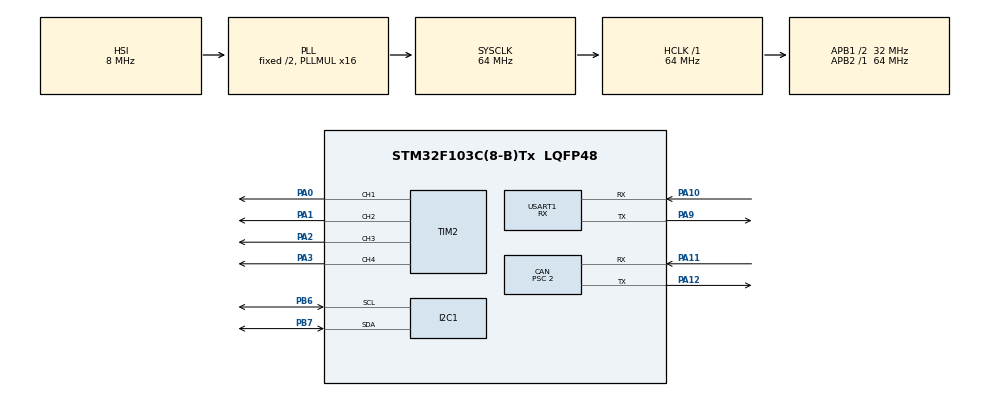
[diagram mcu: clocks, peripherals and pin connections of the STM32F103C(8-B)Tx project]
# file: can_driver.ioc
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CAN.BS1=CAN_BS1_13TQ
CAN.BS2=CAN_BS2_2TQ
CAN.CalculateTimeBit=1000
CAN.CalculateTimeQuantum=62.5
CAN.Mode=CAN_MODE_LOOPBACK
CAN.Prescaler=2
Mcu.Family=STM32F1
Mcu.Name=STM32F103C(8-B)Tx
Mcu.Package=LQFP48
NVIC.PriorityGroup=NVIC_PRIORITYGROUP_4
PA0-WKUP.Signal=S_TIM2_CH1_ETR
PA1.Signal=S_TIM2_CH2
PA10.Mode=Asynchronous
PA10.Signal=USART1_RX
PA11.Mode=Master
PA11.Signal=CAN_RX
PA12.Mode=Master
PA12.Signal=CAN_TX
PA13.Mode=Serial_Wire
PA13.Signal=SYS_JTMS-SWDIO
PA14.Mode=Serial_Wire
PA14.Signal=SYS_JTCK-SWCLK
PA2.Signal=S_TIM2_CH3
PA3.Signal=S_TIM2_CH4
PA9.Mode=Asynchronous
PA9.Signal=USART1_TX
PB6.Mode=I2C
PB6.Signal=I2C1_SCL
PB7.Mode=I2C
PB7.Signal=I2C1_SDA
ProjectManager.HeapSize=0x200
ProjectManager.StackSize=0x400
ProjectManager.TargetToolchain=STM32CubeIDE
RCC.AHBFreq_Value=64000000
RCC.APB1CLKDivider=RCC_HCLK_DIV2
RCC.APB1Freq_Value=32000000
RCC.APB1TimFreq_Value=64000000
RCC.APB2Freq_Value=64000000
RCC.APB2TimFreq_Value=64000000
RCC.HCLKFreq_Value=64000000
RCC.HSE_VALUE=16000000
RCC.PLLMUL=RCC_PLL_MUL16
RCC.SYSCLKFreq_VALUE=64000000
RCC.SYSCLKSource=RCC_SYSCLKSOURCE_PLLCLK
RCC.USBFreq_Value=64000000
SH.S_TIM2_CH1_ETR.0=TIM2_CH1,PWM Generation1 CH1
SH.S_TIM2_CH2.0=TIM2_CH2,PWM Generation2 CH2
SH.S_TIM2_CH3.0=TIM2_CH3,PWM Generation3 CH3
SH.S_TIM2_CH4.0=TIM2_CH4,PWM Generation4 CH4
TIM2.Channel-PWM\ Generation1\ CH1=TIM_CHANNEL_1
TIM2.Channel-PWM\ Generation2\ CH2=TIM_CHANNEL_2
TIM2.Channel-PWM\ Generation3\ CH3=TIM_CHANNEL_3
TIM2.Channel-PWM\ Generation4\ CH4=TIM_CHANNEL_4
USART1.Mode=MODE_RX
USART1.VirtualMode=VM_ASYNC
USART1.WordLength=WORDLENGTH_8B
VP_TIM2_VS_ClockSourceINT.Mode=Internal
board=custom

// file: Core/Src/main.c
/* USER CODE BEGIN Header */
/**
 ******************************************************************************
 * @file           : main.c
 * @brief          : Main program body
 ******************************************************************************
 * @attention
 *
 * <h2><center>&copy; Copyright (c) 2023 STMicroelectronics.
 * All rights reserved.</center></h2>
 *
 * This software component is licensed by ST under BSD 3-Clause license,
 * the "License"; You may not use this file except in compliance with the
 * License. You may obtain a copy of the License at:
 *                        opensource.org/licenses/BSD-3-Clause
 *
 ******************************************************************************
 */
/* USER CODE END Header */
#include "main.h"

CAN_HandleTypeDef hcan;

I2C_HandleTypeDef hi2c1;

TIM_HandleTypeDef htim2;

UART_HandleTypeDef huart1;

void SystemClock_Config(void);
static void MX_GPIO_Init(void);
static void MX_TIM2_Init(void);
static void MX_CAN_Init(void);
static void MX_USART1_UART_Init(void);
static void MX_I2C1_Init(void);

int main(void)
{

  /* MCU Configuration--------------------------------------------------------*/

  /* Reset of all peripherals, Initializes the Flash interface and the Systick. */
  HAL_Init();

  /* Configure the system clock */
  SystemClock_Config();

  /* Initialize all configured peripherals */
  MX_GPIO_Init();
  MX_TIM2_Init();
  MX_CAN_Init();
  MX_USART1_UART_Init();
  MX_I2C1_Init();
  /* USER CODE BEGIN 2 */

	//  Start the CAN module
//	HAL_CAN_Start(&hcan);

//	uint8_t data[8] = {'w','e','g','z','h','e','r','e'};
  /* USER CODE END 2 */

  /* Infinite loop */
	while (1)
	{

	}
}

void SystemClock_Config(void)
{
  RCC_OscInitTypeDef RCC_OscInitStruct = {0};
  RCC_ClkInitTypeDef RCC_ClkInitStruct = {0};

  /** Initializes the RCC Oscillators according to the specified parameters
  * in the RCC_OscInitTypeDef structure.
  */
  RCC_OscInitStruct.OscillatorType = RCC_OSCILLATORTYPE_HSI;
  RCC_OscInitStruct.HSIState = RCC_HSI_ON;
  RCC_OscInitStruct.HSICalibrationValue = RCC_HSICALIBRATION_DEFAULT;
  RCC_OscInitStruct.PLL.PLLState = RCC_PLL_ON;
  RCC_OscInitStruct.PLL.PLLSource = RCC_PLLSOURCE_HSI_DIV2;
  RCC_OscInitStruct.PLL.PLLMUL = RCC_PLL_MUL16;
  if (HAL_RCC_OscConfig(&RCC_OscInitStruct) != HAL_OK)
  {
    Error_Handler();
  }
  /** Initializes the CPU, AHB and APB buses clocks
  */
  RCC_ClkInitStruct.ClockType = RCC_CLOCKTYPE_HCLK|RCC_CLOCKTYPE_SYSCLK
                              |RCC_CLOCKTYPE_PCLK1|RCC_CLOCKTYPE_PCLK2;
  RCC_ClkInitStruct.SYSCLKSource = RCC_SYSCLKSOURCE_PLLCLK;
  RCC_ClkInitStruct.AHBCLKDivider = RCC_SYSCLK_DIV1;
  RCC_ClkInitStruct.APB1CLKDivider = RCC_HCLK_DIV2;
  RCC_ClkInitStruct.APB2CLKDivider = RCC_HCLK_DIV1;

  if (HAL_RCC_ClockConfig(&RCC_ClkInitStruct, FLASH_LATENCY_2) != HAL_OK)
  {
    Error_Handler();
  }
}

static void MX_CAN_Init(void)
{

  hcan.Instance = CAN1;
  hcan.Init.Prescaler = 2;
  hcan.Init.Mode = CAN_MODE_LOOPBACK;
  hcan.Init.SyncJumpWidth = CAN_SJW_1TQ;
  hcan.Init.TimeSeg1 = CAN_BS1_13TQ;
  hcan.Init.TimeSeg2 = CAN_BS2_2TQ;
  hcan.Init.TimeTriggeredMode = DISABLE;
  hcan.Init.AutoBusOff = DISABLE;
  hcan.Init.AutoWakeUp = DISABLE;
  hcan.Init.AutoRetransmission = DISABLE;
  hcan.Init.ReceiveFifoLocked = DISABLE;
  hcan.Init.TransmitFifoPriority = DISABLE;
  if (HAL_CAN_Init(&hcan) != HAL_OK)
  {
    Error_Handler();
  }

}

static void MX_I2C1_Init(void)
{

  hi2c1.Instance = I2C1;
  hi2c1.Init.ClockSpeed = 100000;
  hi2c1.Init.DutyCycle = I2C_DUTYCYCLE_2;
  hi2c1.Init.OwnAddress1 = 0;
  hi2c1.Init.AddressingMode = I2C_ADDRESSINGMODE_7BIT;
  hi2c1.Init.DualAddressMode = I2C_DUALADDRESS_DISABLE;
  hi2c1.Init.OwnAddress2 = 0;
  hi2c1.Init.GeneralCallMode = I2C_GENERALCALL_DISABLE;
  hi2c1.Init.NoStretchMode = I2C_NOSTRETCH_DISABLE;
  if (HAL_I2C_Init(&hi2c1) != HAL_OK)
  {
    Error_Handler();
  }

}

static void MX_TIM2_Init(void)
{

  TIM_ClockConfigTypeDef sClockSourceConfig = {0};
  TIM_MasterConfigTypeDef sMasterConfig = {0};
  TIM_OC_InitTypeDef sConfigOC = {0};

  htim2.Instance = TIM2;
  htim2.Init.Prescaler = 0;
  htim2.Init.CounterMode = TIM_COUNTERMODE_UP;
  htim2.Init.Period = 65535;
  htim2.Init.ClockDivision = TIM_CLOCKDIVISION_DIV1;
  htim2.Init.AutoReloadPreload = TIM_AUTORELOAD_PRELOAD_DISABLE;
  if (HAL_TIM_Base_Init(&htim2) != HAL_OK)
  {
    Error_Handler();
  }
  sClockSourceConfig.ClockSource = TIM_CLOCKSOURCE_INTERNAL;
  if (HAL_TIM_ConfigClockSource(&htim2, &sClockSourceConfig) != HAL_OK)
  {
    Error_Handler();
  }
  if (HAL_TIM_PWM_Init(&htim2) != HAL_OK)
  {
    Error_Handler();
  }
  sMasterConfig.MasterOutputTrigger = TIM_TRGO_RESET;
  sMasterConfig.MasterSlaveMode = TIM_MASTERSLAVEMODE_DISABLE;
  if (HAL_TIMEx_MasterConfigSynchronization(&htim2, &sMasterConfig) != HAL_OK)
  {
    Error_Handler();
  }
  sConfigOC.OCMode = TIM_OCMODE_PWM1;
  sConfigOC.Pulse = 0;
  sConfigOC.OCPolarity = TIM_OCPOLARITY_HIGH;
  sConfigOC.OCFastMode = TIM_OCFAST_DISABLE;
  if (HAL_TIM_PWM_ConfigChannel(&htim2, &sConfigOC, TIM_CHANNEL_1) != HAL_OK)
  {
    Error_Handler();
  }
  if (HAL_TIM_PWM_ConfigChannel(&htim2, &sConfigOC, TIM_CHANNEL_2) != HAL_OK)
  {
    Error_Handler();
  }
  if (HAL_TIM_PWM_ConfigChannel(&htim2, &sConfigOC, TIM_CHANNEL_3) != HAL_OK)
  {
    Error_Handler();
  }
  if (HAL_TIM_PWM_ConfigChannel(&htim2, &sConfigOC, TIM_CHANNEL_4) != HAL_OK)
  {
    Error_Handler();
  }
  HAL_TIM_MspPostInit(&htim2);

}

static void MX_USART1_UART_Init(void)
{

  huart1.Instance = USART1;
  huart1.Init.BaudRate = 115200;
  huart1.Init.WordLength = UART_WORDLENGTH_8B;
  huart1.Init.StopBits = UART_STOPBITS_1;
  huart1.Init.Parity = UART_PARITY_NONE;
  huart1.Init.Mode = UART_MODE_RX;
  huart1.Init.HwFlowCtl = UART_HWCONTROL_NONE;
  huart1.Init.OverSampling = UART_OVERSAMPLING_16;
  if (HAL_UART_Init(&huart1) != HAL_OK)
  {
    Error_Handler();
  }

}

static void MX_GPIO_Init(void)
{

  /* GPIO Ports Clock Enable */
  __HAL_RCC_GPIOA_CLK_ENABLE();
  __HAL_RCC_GPIOB_CLK_ENABLE();

}

void Error_Handler(void)
{
}

/************************ (C) COPYRIGHT STMicroelectronics *****END OF FILE****/
